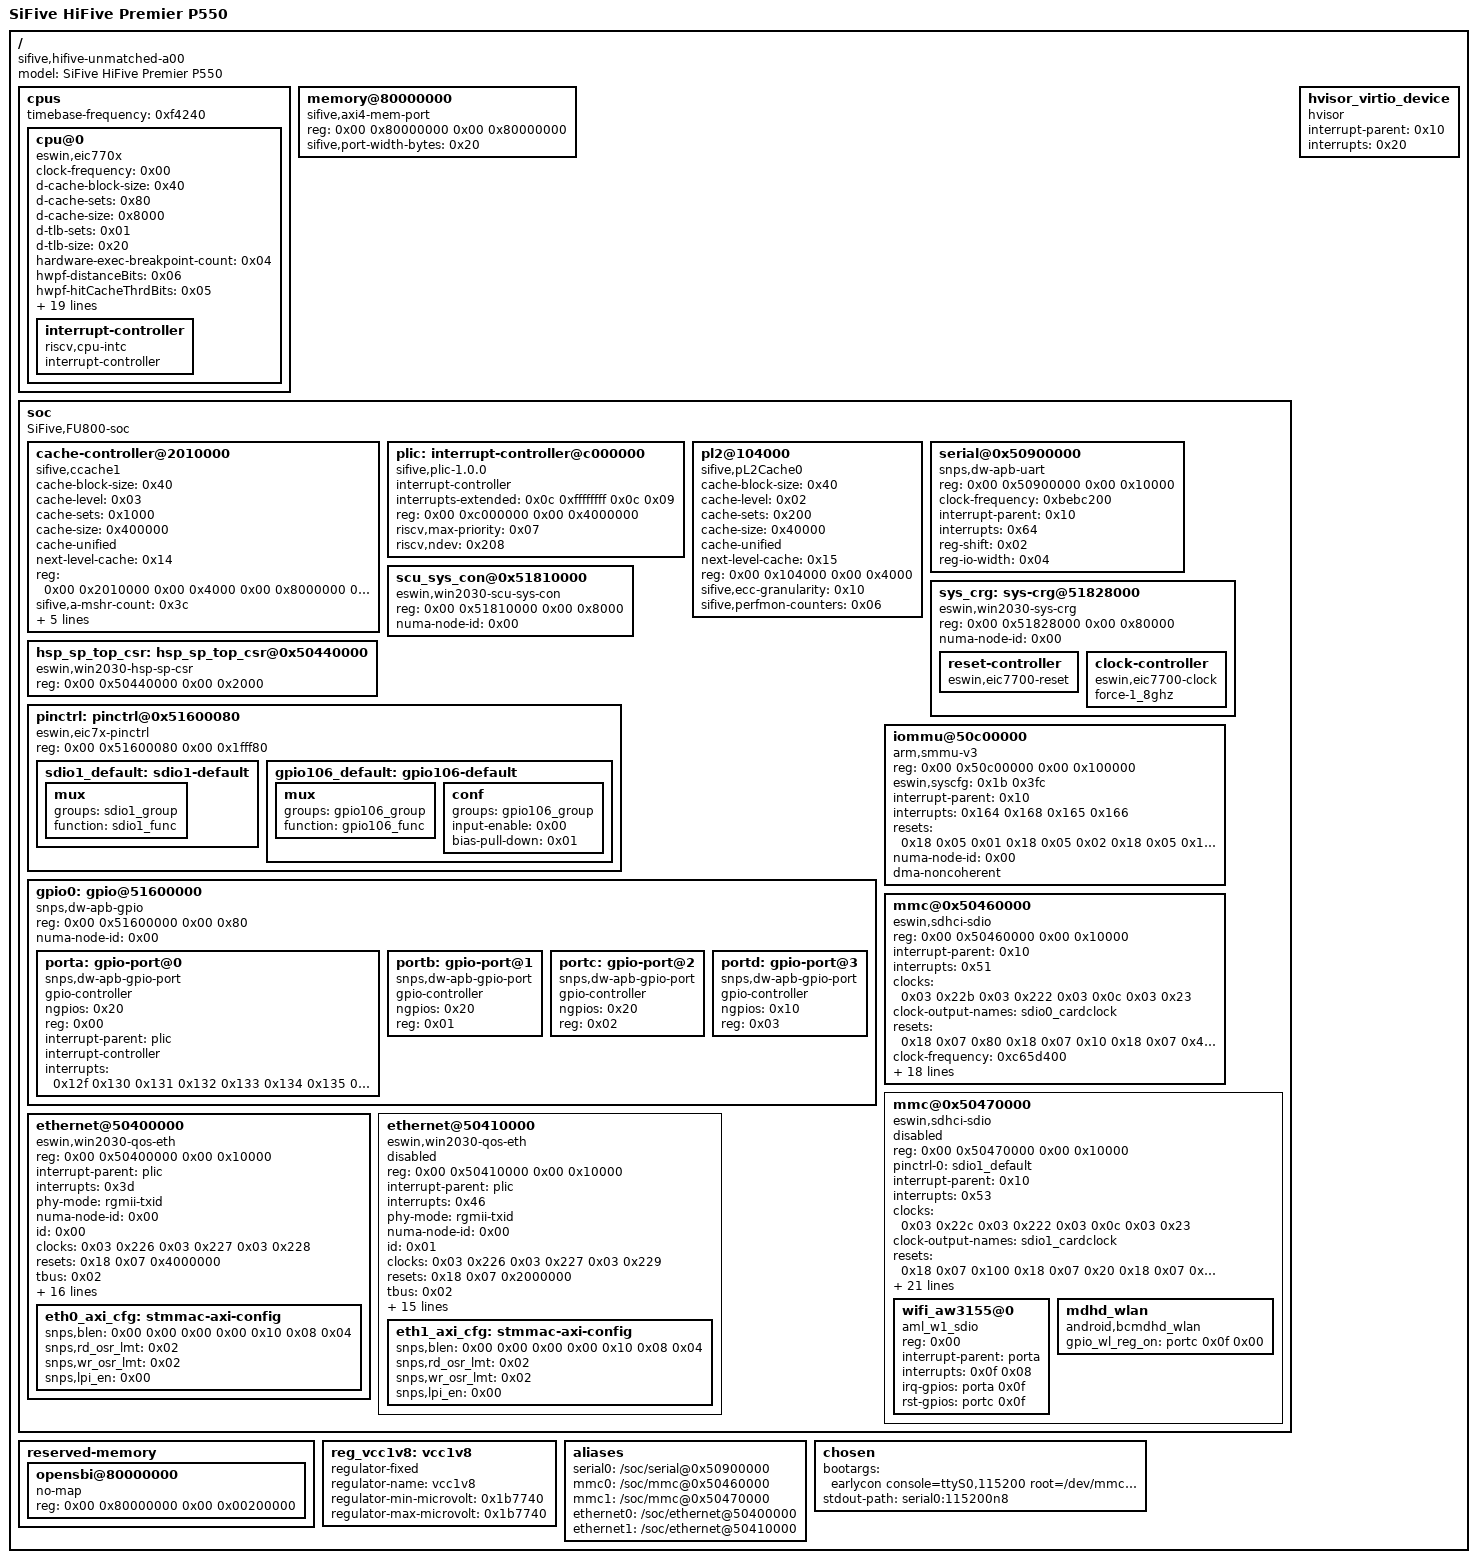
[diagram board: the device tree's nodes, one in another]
/dts-v1/;

/ {
	#address-cells = <0x02>;
	#size-cells = <0x02>;
	compatible = "sifive,hifive-unmatched-a00\0sifive,fu740-c000\0sifive,fu740\0eswin,eic7700";
	model = "SiFive HiFive Premier P550";

	cpus {
		#address-cells = <0x01>;
		#size-cells = <0x00>;
		timebase-frequency = <0xf4240>;

		cpu@0 {
			clock-frequency = <0x00>;
			compatible = "eswin,eic770x\0riscv";
			d-cache-block-size = <0x40>;
			d-cache-sets = <0x80>;
			d-cache-size = <0x8000>;
			d-tlb-sets = <0x01>;
			d-tlb-size = <0x20>;
			device_type = "cpu";
			hardware-exec-breakpoint-count = <0x04>;
			hwpf-distanceBits = <0x06>;
			hwpf-hitCacheThrdBits = <0x05>;
			hwpf-hitMSHRThrdBits = <0x04>;
			hwpf-l2pfPoolSize = <0x0a>;
			hwpf-nIssQEnt = <0x06>;
			hwpf-nPrefetchQueueEntries = <0x08>;
			hwpf-nStreams = <0x10>;
			hwpf-qFullnessThrdBits = <0x04>;
			hwpf-windowBits = <0x06>;
			i-cache-block-size = <0x40>;
			i-cache-sets = <0x80>;
			i-cache-size = <0x8000>;
			i-tlb-sets = <0x01>;
			i-tlb-size = <0x20>;
			mmu-type = "riscv,sv48";
			next-level-cache = <0x01>;
			reg = <0x00>;
			riscv,isa = "rv64imafdc";
			status = "okay";
			timebase-frequency = <0xf4240>;
			tlb-split;
			clocks = <0x03 0x1f4>;
			phandle = <0x4a>;

			interrupt-controller {
				#interrupt-cells = <0x01>;
				compatible = "riscv,cpu-intc";
				interrupt-controller;
				phandle = <0x0c>;
			};
		};
	};

	memory@80000000 {
		compatible = "sifive,axi4-mem-port\0sifive,axi4-port\0sifive,mem-port";
		device_type = "memory";
		reg = <0x00 0x80000000 0x00 0x80000000>;
		sifive,port-width-bytes = <0x20>;
		phandle = <0x14>;
	};

	soc {
		#address-cells = <0x02>;
		#size-cells = <0x02>;
		compatible = "SiFive,FU800-soc\0fu800-soc\0sifive-soc\0simple-bus";
		ranges;

		cache-controller@2010000 {
			cache-block-size = <0x40>;
			cache-level = <0x03>;
			cache-sets = <0x1000>;
			cache-size = <0x400000>;
			cache-unified;
			compatible = "sifive,ccache1\0cache\0sifive,fu740-c000-ccache";
			// interrupt-parent = <0x10>;
			// interrupts = <0x01 0x03 0x04 0x02>;
			next-level-cache = <0x14>;
			reg = <0x00 0x2010000 0x00 0x4000 0x00 0x8000000 0x00 0x400000>;
			reg-names = "control\0sideband";
			sifive,a-mshr-count = <0x3c>;
			sifive,bank-count = <0x04>;
			sifive,ecc-granularity = <0x08>;
			sifive,max-master-id = <0x0d>;
			sifive,perfmon-counters = <0x06>;
			numa-node-id = <0x00>;
			phandle = <0x15>;
		};

		plic: interrupt-controller@c000000 {
			#interrupt-cells = <0x01>;
			compatible = "sifive,plic-1.0.0";
			interrupt-controller;
			interrupts-extended = <0x0c 0xffffffff 0x0c 0x09>;
			reg = <0x00 0xc000000 0x00 0x4000000>;
			reg-names = "control";
			riscv,max-priority = <0x07>;
			riscv,ndev = <0x208>;
			phandle = <0x10>;
		};

		pl2@104000 {
			cache-block-size = <0x40>;
			cache-level = <0x02>;
			cache-sets = <0x200>;
			cache-size = <0x40000>;
			cache-unified;
			compatible = "sifive,pL2Cache0\0cache";
			next-level-cache = <0x15>;
			reg = <0x00 0x104000 0x00 0x4000>;
			reg-names = "control";
			sifive,ecc-granularity = <0x10>;
			sifive,perfmon-counters = <0x06>;
			phandle = <0x01>;
		};

		serial@0x50900000 {
			compatible = "snps,dw-apb-uart";
			reg = <0x00 0x50900000 0x00 0x10000>;
			clock-frequency = <0xbebc200>;
			interrupt-parent = <0x10>;
			interrupts = <0x64>;
			reg-shift = <0x02>;
			reg-io-width = <0x04>;
			status = "okay";
		};

		// serial@0x50920000 {
		// 	compatible = "snps,dw-apb-uart";
		// 	reg = <0x00 0x50920000 0x00 0x10000>;
		// 	clock-frequency = <0xbebc200>;
		// 	interrupt-parent = <0x10>;
		// 	interrupts = <0x66>;
		// 	reg-shift = <0x02>;
		// 	reg-io-width = <0x04>;
		// 	status = "okay";
		// };

		sys_crg: sys-crg@51828000 {
			compatible = "eswin,win2030-sys-crg\0syscon\0simple-mfd";
			reg = <0x00 0x51828000 0x00 0x80000>;
			numa-node-id = <0x00>;
			phandle = <0x16>;

			reset-controller {
				compatible = "eswin,eic7700-reset";
				#reset-cells = <0x02>;
				status = "okay";
				phandle = <0x18>;
			};

			clock-controller {
				compatible = "eswin,eic7700-clock";
				#clock-cells = <0x01>;
				status = "okay";
				force-1_8ghz;
				phandle = <0x03>;
			};
		};

		scu_sys_con@0x51810000 {
			compatible = "eswin,win2030-scu-sys-con\0syscon\0simple-mfd";
			#syscon-cells = <0x02>;
			#size-cells = <0x02>;
			reg = <0x00 0x51810000 0x00 0x8000>;
			numa-node-id = <0x00>;
			phandle = <0x1b>;
		};

		hsp_sp_top_csr: hsp_sp_top_csr@0x50440000 {
			compatible = "eswin,win2030-hsp-sp-csr\0syscon";
			#size-cells = <0x02>;
			reg = <0x00 0x50440000 0x00 0x2000>;
			phandle = <0x1a>;
		};

		pinctrl: pinctrl@0x51600080 {
			compatible = "eswin,eic7x-pinctrl\0syscon";
			reg = <0x00 0x51600080 0x00 0x1fff80>;
			status = "okay";

			sdio1_default: sdio1-default {
				mux {
					groups = "sdio1_group";
					function = "sdio1_func";
				};
			};

			gpio106_default: gpio106-default {
				mux {
					groups = "gpio106_group";
					function = "gpio106_func";
				};

				conf {
					groups = "gpio106_group";
					input-enable = <0x00>;
					bias-pull-down = <0x01>;
				};
			};
		};

		gpio0: gpio@51600000 {
			#address-cells = <0x01>;
			#size-cells = <0x00>;
			compatible = "snps,dw-apb-gpio";
			reg = <0x00 0x51600000 0x00 0x80>;
			numa-node-id = <0x00>;

			porta: gpio-port@0 {
				compatible = "snps,dw-apb-gpio-port";
				gpio-controller;
				#gpio-cells = <0x02>;
				ngpios = <0x20>;
				reg = <0x00>;
				interrupt-parent = <&plic>;
				interrupt-controller;
				#interrupt-cells = <0x02>;
				interrupts = <0x12f 0x130 0x131 0x132 0x133 0x134 0x135 0x136 0x137 0x138 0x139 0x13a 0x13b 0x13c 0x13d 0x13e
					      0x13f 0x140 0x141 0x142 0x143 0x144 0x145 0x146 0x147 0x148 0x149 0x14a 0x14b 0x14c 0x14d 0x14e>;
			};

			portb: gpio-port@1 {
				compatible = "snps,dw-apb-gpio-port";
				gpio-controller;
				#gpio-cells = <0x02>;
				ngpios = <0x20>;
				reg = <0x01>;
			};

			portc: gpio-port@2 {
				compatible = "snps,dw-apb-gpio-port";
				gpio-controller;
				#gpio-cells = <0x02>;
				ngpios = <0x20>;
				reg = <0x02>;
			};

			portd: gpio-port@3 {
				compatible = "snps,dw-apb-gpio-port";
				gpio-controller;
				#gpio-cells = <0x02>;
				ngpios = <0x10>;
				reg = <0x03>;
			};
		};

		iommu@50c00000 {
			compatible = "arm,smmu-v3";
			reg = <0x00 0x50c00000 0x00 0x100000>;
			eswin,syscfg = <0x1b 0x3fc>;
			interrupt-parent = <0x10>;
			interrupts = <0x164 0x168 0x165 0x166>;
			interrupt-names = "eventq\0gerror\0priq\0cmdq-sync";
			#iommu-cells = <0x01>;
			resets = <0x18 0x05 0x01 0x18 0x05 0x02 0x18 0x05 0x10 0x18 0x05 0x20 0x18 0x05 0x40 0x18 0x05 0x80 0x18 0x05 0x100 0x18 0x05 0x200 0x18 0x05 0x400 0x18 0x05 0x800>;
			reset-names = "axi_rst\0cfg_rst\0tbu0_rst\0tbu1_rst\0tbu2_rst\0tbu3_rst\0tbu4_rst\0tbu5_rst\0tbu6_rst\0tbu7_rst";
			status = "okay";
			numa-node-id = <0x00>;
			dma-noncoherent;
			phandle = <0x1c>;
		};

		mmc@0x50460000 {
			compatible = "eswin,sdhci-sdio";
			reg = <0x00 0x50460000 0x00 0x10000>;
			interrupt-parent = <0x10>;
			interrupts = <0x51>;
			clocks = <0x03 0x22b 0x03 0x222 0x03 0x0c 0x03 0x23>;
			clock-names = "clk_xin\0clk_ahb\0clk_spll2_fout3\0clk_mux1_1";
			clock-output-names = "sdio0_cardclock";
			#clock-cells = <0x00>;
			resets = <0x18 0x07 0x80 0x18 0x07 0x10 0x18 0x07 0x40000 0x18 0x07 0x400000>;
			reset-names = "txrx_rst\0phy_rst\0prstn\0arstn";
			clock-frequency = <0xc65d400>;
			max-frequency = <0xc65d400>;
			#address-cells = <0x01>;
			#size-cells = <0x00>;
			dma-ranges = <0x00 0x20000000 0x00 0xc0000000 0x00 0x40000000>;
			iommus = <0x1c 0x10>;
			tbus = <0x02>;
			eswin,hsp_sp_csr = <0x1a 0x103c 0x608 0x60c>;
			eswin,syscrg_csr = <0x16 0x164 0x148 0x14c>;
			bus-width = <0x04>;
			sdio-id = <0x00>;
			numa-node-id = <0x00>;
			status = "okay";
			dma-noncoherent;
			delay_code = <0x55>;
			drive-impedance-ohm = <0x21>;
			enable-cmd-pullup;
			enable-data-pullup;
			no-sdio;
			no-mmc;
			non-removable;
		};

		mmc@0x50470000 {
			compatible = "eswin,sdhci-sdio";
			reg = <0x00 0x50470000 0x00 0x10000>;
			pinctrl-names = "default";
			pinctrl-0 = <&sdio1_default>;
			interrupt-parent = <0x10>;
			interrupts = <0x53>;
			clocks = <0x03 0x22c 0x03 0x222 0x03 0x0c 0x03 0x23>;
			clock-names = "clk_xin\0clk_ahb\0clk_spll2_fout3\0clk_mux1_1";
			clock-output-names = "sdio1_cardclock";
			#clock-cells = <0x00>;
			resets = <0x18 0x07 0x100 0x18 0x07 0x20 0x18 0x07 0x20000 0x18 0x07 0x200000>;
			reset-names = "txrx_rst\0phy_rst\0prstn\0arstn";
			clock-frequency = <0xc65d400>;
			max-frequency = <0xc65d400>;
			#address-cells = <0x01>;
			#size-cells = <0x00>;
			dma-ranges = <0x00 0x20000000 0x00 0xc0000000 0x00 0x40000000>;
			iommus = <0x1c 0x11>;
			tbus = <0x02>;
			eswin,hsp_sp_csr = <0x1a 0x1040 0x708 0x70c>;
			eswin,syscrg_csr = <0x16 0x168 0x148 0x14c>;
			bus-width = <0x04>;
			sdio-id = <0x01>;
			numa-node-id = <0x00>;
			status = "disabled";
			dma-noncoherent;
			delay_code = <0x29>;
			drive-impedance-ohm = <0x21>;
			enable-cmd-pullup;
			enable-data-pullup;
			non-removable;
			keep-power-in-suspend;
			no-sd;
			no-mmc;
			vqmmc-supply = <&reg_vcc1v8>;

			wifi_aw3155@0 {
				compatible = "aml_w1_sdio";
				reg = <0x00>;
				interrupt-parent = <&porta>;
				interrupts = <0x0f 0x08>;
				irq-gpios = <&porta 0x0f 0x00>;
				rst-gpios = <&portc 0x0f 0x00>;
			};

			mdhd_wlan {
				compatible = "android,bcmdhd_wlan";
				gpio_wl_reg_on = <&portc 0x0f 0x00>;
			};
		};

		ethernet@50400000 {
			compatible = "eswin,win2030-qos-eth";
			reg = <0x00 0x50400000 0x00 0x10000>;
			interrupt-parent = <&plic>;
			interrupt-names = "macirq";
			interrupts = <0x3d>;
			phy-mode = "rgmii-txid";
			numa-node-id = <0x00>;
			id = <0x00>;
			status = "okay";
			clocks = <0x03 0x226 0x03 0x227 0x03 0x228>;
			clock-names = "app\0stmmaceth\0tx";
			resets = <0x18 0x07 0x4000000>;
			reset-names = "ethrst";
			tbus = <0x02>;
			dma-noncoherent;
			eswin,hsp_sp_csr = <&hsp_sp_top_csr 0x1030 0x100 0x108>;
			eswin,syscrg_csr = <&sys_crg 0x148 0x14c>;
			pinctrl-names = "default";
			pinctrl-0 = <&gpio106_default>;
			rst-gpios = <&portd 10 1>;
			eswin,rgmiisel = <&pinctrl 0x290 0x3>;
			eswin,phyaddr = <0x0>;
			eswin,dly_hsp_reg = <0x114 0x118 0x11c>;
			snps,axi-config = <&eth0_axi_cfg>;
			eswin,led-cfgs = <0x6100 0xa40 0x420>;
			dly-param-1000m = <0x20202020 0x96205a20 0x20202020>;
			dly-param-100m = <0x20202020 0x96205a20 0x20202020>;
			dly-param-10m = <0x00 0x00 0x00>;

			eth0_axi_cfg: stmmac-axi-config {
				snps,blen = <0x00 0x00 0x00 0x00 0x10 0x08 0x04>;
				snps,rd_osr_lmt = <0x02>;
				snps,wr_osr_lmt = <0x02>;
				snps,lpi_en = <0x00>;
			};
	};

		ethernet@50410000 {
			compatible = "eswin,win2030-qos-eth";
			reg = <0x00 0x50410000 0x00 0x10000>;
			interrupt-parent = <&plic>;
			interrupt-names = "macirq";
			interrupts = <0x46>;
			phy-mode = "rgmii-txid";
			numa-node-id = <0x00>;
			id = <0x01>;
			status = "disabled";
			clocks = <0x03 0x226 0x03 0x227 0x03 0x229>;
			clock-names = "app\0stmmaceth\0tx";
			resets = <0x18 0x07 0x2000000>;
			reset-names = "ethrst";
			tbus = <0x02>;
			dma-noncoherent;
			eswin,hsp_sp_csr = <&hsp_sp_top_csr 0x1034 0x200 0x208>;
			eswin,syscrg_csr = <&sys_crg 0x148 0x14c>;
			rst-gpios = <&portd 15 1>;
			eswin,rgmiisel = <&pinctrl 0x294 0x3>;
			eswin,phyaddr = <0x0>;
			eswin,dly_hsp_reg = <0x214 0x218 0x21c>;
			snps,axi-config = <&eth1_axi_cfg>;
			eswin,led-cfgs = <0x6100 0xa40 0x420>;
			dly-param-1000m = <0x20202020 0x46204620 0x20202020>;
			dly-param-100m = <0x20202020 0x50205020 0x20202020>;
			dly-param-10m = <0x00 0x00 0x00>;

			eth1_axi_cfg: stmmac-axi-config {
				snps,blen = <0x00 0x00 0x00 0x00 0x10 0x08 0x04>;
				snps,rd_osr_lmt = <0x02>;
				snps,wr_osr_lmt = <0x02>;
				snps,lpi_en = <0x00>;
			};
		};
	};

	reserved-memory {
		#address-cells = <0x02>;
		#size-cells = <0x02>;
		ranges;

		opensbi@80000000 {
			no-map;
			reg = <0x00 0x80000000 0x00 0x00200000>;
		};

//		hvisor@80200000 {
//			no-map;
//			reg = <0x00 0x80200000 0x00 0x02E00000>;
//		};
//
//		nonroot@0x83000000 {
//			no-map;
//			reg = <0x00 0x83000000 0x00 0x0C000000>;
//		};
//
//		dtbfile@0x8f000000 {
//			no-map;
//			reg = <0x00 0x8f000000 0x00 0x01000000>;
//		};
//		
//		virtio-dma@9400000 {
//			reg = <0x0 0x09400000 0x0 0x10000>;
//			no-map;
//		};
	};

	hvisor_virtio_device {
		compatible = "hvisor";
    	interrupt-parent = <0x10>;
    	interrupts = <0x20>;
	};

	reg_vcc1v8: vcc1v8 {
		compatible = "regulator-fixed";
		regulator-name = "vcc1v8";
		regulator-min-microvolt = <0x1b7740>;
		regulator-max-microvolt = <0x1b7740>;
	};

	aliases {
		serial0 = "/soc/serial@0x50900000";
		mmc0 = "/soc/mmc@0x50460000";
		mmc1 = "/soc/mmc@0x50470000";
		ethernet0 = "/soc/ethernet@50400000";
		ethernet1 = "/soc/ethernet@50410000";
		// serial2 = "/soc/serial@0x50920000";
	};

	chosen {
		bootargs = "earlycon console=ttyS0,115200 root=/dev/mmcblk0p3 rootfstype=ext4 rw rootwait init=/bin/bash";
		stdout-path = "serial0:115200n8";
		// bootargs = "earlycon console=ttyS2,115200 root=/dev/mmcblk0p3 rootfstype=ext4 rw rootwait init=/bin/bash";
		// stdout-path = "serial2:115200n8";
	};
};
